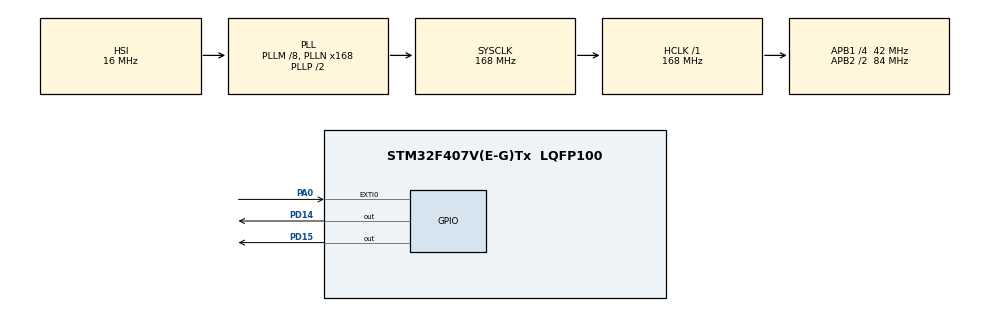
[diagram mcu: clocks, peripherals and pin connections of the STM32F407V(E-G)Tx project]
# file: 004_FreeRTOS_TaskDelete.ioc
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Mcu.Family=STM32F4
Mcu.Name=STM32F407V(E-G)Tx
Mcu.Package=LQFP100
NVIC.EXTI0_IRQn=true\:0\:0\:false\:false\:true\:true\:true\:true
NVIC.PriorityGroup=NVIC_PRIORITYGROUP_4
NVIC.TIM6_DAC_IRQn=true\:0\:0\:false\:false\:true\:false\:true\:true
NVIC.TimeBase=TIM6_DAC_IRQn
NVIC.TimeBaseIP=TIM6
PA0-WKUP.Signal=GPXTI0
PA13.Mode=Serial_Wire
PA13.Signal=SYS_JTMS-SWDIO
PA14.Mode=Serial_Wire
PA14.Signal=SYS_JTCK-SWCLK
PD14.Signal=GPIO_Output
PD15.Signal=GPIO_Output
PH0-OSC_IN.Mode=HSE-External-Oscillator
PH0-OSC_IN.Signal=RCC_OSC_IN
PH1-OSC_OUT.Mode=HSE-External-Oscillator
PH1-OSC_OUT.Signal=RCC_OSC_OUT
ProjectManager.HeapSize=0x200
ProjectManager.StackSize=0x400
ProjectManager.TargetToolchain=STM32CubeIDE
RCC.48MHZClocksFreq_Value=48000000
RCC.AHBFreq_Value=168000000
RCC.APB1CLKDivider=RCC_HCLK_DIV4
RCC.APB1Freq_Value=42000000
RCC.APB1TimFreq_Value=84000000
RCC.APB2CLKDivider=RCC_HCLK_DIV2
RCC.APB2Freq_Value=84000000
RCC.APB2TimFreq_Value=168000000
RCC.CortexFreq_Value=168000000
RCC.HCLKFreq_Value=168000000
RCC.HSE_VALUE=8000000
RCC.HSI_VALUE=16000000
RCC.LSE_VALUE=32768
RCC.PLLM=8
RCC.PLLN=168
RCC.PLLQ=7
RCC.SYSCLKFreq_VALUE=168000000
RCC.SYSCLKSource=RCC_SYSCLKSOURCE_PLLCLK
RCC.VCOOutputFreq_Value=336000000
VP_SYS_VS_tim6.Mode=TIM6
board=STM32F407G-DISC1

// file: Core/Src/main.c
/* USER CODE BEGIN Header */
/**
  ******************************************************************************
  * @file           : main.c
  * @brief          : Main program body
  ******************************************************************************
  * @attention
  *
  * <h2><center>&copy; Copyright (c) 2021 STMicroelectronics.
  * All rights reserved.</center></h2>
  *
  * This software component is licensed by ST under BSD 3-Clause license,
  * the "License"; You may not use this file except in compliance with the
  * License. You may obtain a copy of the License at:
  *                        opensource.org/licenses/BSD-3-Clause
  *
  ******************************************************************************
  */
/* USER CODE END Header */

#include "main.h"

/* USER CODE BEGIN Includes */
#include <stdio.h>
#include "FreeRTOS.h"
#include "task.h"

/* USER CODE END Includes */

/* USER CODE BEGIN PV */

#define DWT_CTRL    (*(volatile uint32_t*)0xE0001000)

/* USER CODE END PV */

void SystemClock_Config(void);
static void MX_GPIO_Init(void);
/* USER CODE BEGIN PFP */

static void task1_handler(void* parameters);
static void task2_handler(void* parameters);
void rtos_delay(int ms);

extern  void SEGGER_UART_init(uint32_t);

/* USER CODE END PFP */

int main(void)
{
  /* USER CODE BEGIN 1 */

	TaskHandle_t task1_handle;
	TaskHandle_t task2_handle;

	BaseType_t status;

  /* USER CODE END 1 */

  /* MCU Configuration--------------------------------------------------------*/

  /* Reset of all peripherals, Initializes the Flash interface and the Systick. */
  HAL_Init();

  /* Configure the system clock */
  SystemClock_Config();

  /* Initialize all configured peripherals */
  MX_GPIO_Init();
  /* USER CODE BEGIN 2 */

  //Enable the CYCCNT counter.
  DWT_CTRL |= ( 1 << 0);

  SEGGER_UART_init(500000);

  SEGGER_SYSVIEW_Conf();

  SEGGER_SYSVIEW_Start();

  status = xTaskCreate(task1_handler, "Task-1", configMINIMAL_STACK_SIZE, NULL, 1, &task1_handle);

  configASSERT(status == pdPASS);

  status = xTaskCreate(task2_handler, "Task-2", configMINIMAL_STACK_SIZE, NULL, 2, &task2_handle);

  configASSERT(status == pdPASS);

  //start the freeRTOS scheduler
  vTaskStartScheduler();

  //if the control comes here, then the launch of the scheduler has failed due to
  //insufficient memory in heap

  /* USER CODE END 2 */

  /* Infinite loop */
  while (1)
  {

  }
}

void SystemClock_Config(void)
{
  RCC_OscInitTypeDef RCC_OscInitStruct = {0};
  RCC_ClkInitTypeDef RCC_ClkInitStruct = {0};

  /** Configure the main internal regulator output voltage
  */
  __HAL_RCC_PWR_CLK_ENABLE();
  __HAL_PWR_VOLTAGESCALING_CONFIG(PWR_REGULATOR_VOLTAGE_SCALE1);
  /** Initializes the CPU, AHB and APB busses clocks
  */
  RCC_OscInitStruct.OscillatorType = RCC_OSCILLATORTYPE_HSI;
  RCC_OscInitStruct.HSIState = RCC_HSI_ON;
  RCC_OscInitStruct.HSICalibrationValue = RCC_HSICALIBRATION_DEFAULT;
  RCC_OscInitStruct.PLL.PLLState = RCC_PLL_ON;
  RCC_OscInitStruct.PLL.PLLSource = RCC_PLLSOURCE_HSI;
  RCC_OscInitStruct.PLL.PLLM = 8;
  RCC_OscInitStruct.PLL.PLLN = 168;
  RCC_OscInitStruct.PLL.PLLP = RCC_PLLP_DIV2;
  RCC_OscInitStruct.PLL.PLLQ = 7;
  if (HAL_RCC_OscConfig(&RCC_OscInitStruct) != HAL_OK)
  {
    Error_Handler();
  }
  /** Initializes the CPU, AHB and APB busses clocks
  */
  RCC_ClkInitStruct.ClockType = RCC_CLOCKTYPE_HCLK|RCC_CLOCKTYPE_SYSCLK
                              |RCC_CLOCKTYPE_PCLK1|RCC_CLOCKTYPE_PCLK2;
  RCC_ClkInitStruct.SYSCLKSource = RCC_SYSCLKSOURCE_PLLCLK;
  RCC_ClkInitStruct.AHBCLKDivider = RCC_SYSCLK_DIV1;
  RCC_ClkInitStruct.APB1CLKDivider = RCC_HCLK_DIV4;
  RCC_ClkInitStruct.APB2CLKDivider = RCC_HCLK_DIV2;

  if (HAL_RCC_ClockConfig(&RCC_ClkInitStruct, FLASH_LATENCY_5) != HAL_OK)
  {
    Error_Handler();
  }
}

static void MX_GPIO_Init(void)
{
  GPIO_InitTypeDef GPIO_InitStruct = {0};

  /* GPIO Ports Clock Enable */
  __HAL_RCC_GPIOH_CLK_ENABLE();
  __HAL_RCC_GPIOA_CLK_ENABLE();
  __HAL_RCC_GPIOD_CLK_ENABLE();

  /*Configure GPIO pin Output Level */
  HAL_GPIO_WritePin(GPIOD, GPIO_PIN_14|GPIO_PIN_15, GPIO_PIN_RESET);

  /*Configure GPIO pin : PA0 */
  GPIO_InitStruct.Pin = GPIO_PIN_0;
  GPIO_InitStruct.Mode = GPIO_MODE_IT_RISING;
  GPIO_InitStruct.Pull = GPIO_NOPULL;
  HAL_GPIO_Init(GPIOA, &GPIO_InitStruct);

  /*Configure GPIO pins : PD14 PD15 */
  GPIO_InitStruct.Pin = GPIO_PIN_14|GPIO_PIN_15;
  GPIO_InitStruct.Mode = GPIO_MODE_OUTPUT_PP;
  GPIO_InitStruct.Pull = GPIO_NOPULL;
  GPIO_InitStruct.Speed = GPIO_SPEED_FREQ_LOW;
  HAL_GPIO_Init(GPIOD, &GPIO_InitStruct);

  /* EXTI interrupt init*/
  HAL_NVIC_SetPriority(EXTI0_IRQn, 0, 0);
  HAL_NVIC_EnableIRQ(EXTI0_IRQn);

}

/* USER CODE BEGIN 4 */

static void task1_handler(void* parameters)
{
	// tongle led 1 1s
	// press btn -> task delete
	while(1)
	{
		HAL_GPIO_TogglePin(GPIOD, GPIO_PIN_15);
	}

}

static void task2_handler(void* parameters)
{
	// tongle led 2 200ms
	while(1)
	{
		if(HAL_GPIO_ReadPin(GPIOA, GPIO_PIN_0) == 1)
		{
			vTaskDelete(NULL);
		}
		HAL_GPIO_TogglePin(GPIOD, GPIO_PIN_15);
	}

}

void rtos_delay(int ms)
{

}

//void HAL_GPIO_EXTI_Callback(uint16_t GPIO_Pin)
//{
//
//}

/* USER CODE END 4 */

void HAL_TIM_PeriodElapsedCallback(TIM_HandleTypeDef *htim)
{
  if (htim->Instance == TIM6) {
    HAL_IncTick();
  }
}

void Error_Handler(void)
{
}

/************************ (C) COPYRIGHT STMicroelectronics *****END OF FILE****/
